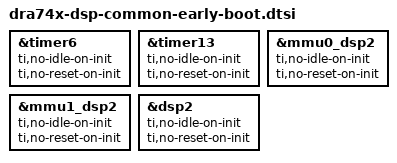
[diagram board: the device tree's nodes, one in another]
// SPDX-License-Identifier: GPL-2.0
/*
 * Copyright (C) 2019 Texas Instruments Incorporated - http://www.ti.com/
 *
 * Common dtsi file that needs to be included in corresponding TI DRA7xx
 * and AM57xx board dts files that have the DSP2 remote processor
 * booted early from TI U-Boot/SPL.
 */

/* DSP2 */
&timer6 {
	ti,no-idle-on-init;
	ti,no-reset-on-init;
};

&timer13 {
	ti,no-idle-on-init;
	ti,no-reset-on-init;
};

&mmu0_dsp2{
	ti,no-idle-on-init;
	ti,no-reset-on-init;
};

&mmu1_dsp2{
	ti,no-idle-on-init;
	ti,no-reset-on-init;
};
&dsp2 {
	ti,no-idle-on-init;
	ti,no-reset-on-init;
};


